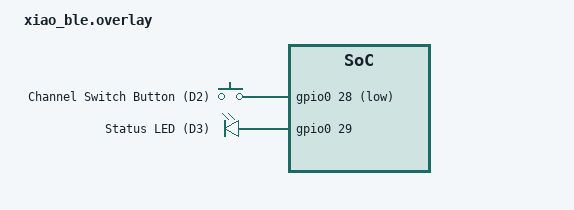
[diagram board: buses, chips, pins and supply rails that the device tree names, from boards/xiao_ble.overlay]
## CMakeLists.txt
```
cmake_minimum_required(VERSION 3.20.0)

find_package(Zephyr REQUIRED HINTS $ENV{ZEPHYR_BASE})
project(multichannel_ble_keyboard)

target_sources(app PRIVATE
    src/main.c
    src/hid_keyboard.c
)
```

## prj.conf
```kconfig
# ---------------------------------------------------------------------------
# Multi-Channel BLE Keyboard - prj.conf
# XIAO nRF52840 (Plus) + Zephyr
# ---------------------------------------------------------------------------

# --- GPIO (button + LED) ---
CONFIG_GPIO=y

# --- Bluetooth core ---
CONFIG_BT=y
CONFIG_BT_PERIPHERAL=y
CONFIG_BT_DEVICE_NAME="BTSwitchIRK"

# Allow multiple local identities = multiple "channels".
# Must be >= NUM_CHANNELS used in main.c (id 0 is the default identity).
CONFIG_BT_ID_MAX=4

# Only one *logical* BLE link at a time (one channel connected at once),
# but we allocate 2 connection object slots. Connectable advertising
# preallocates a connection object, and the object from the just-ended
# link may not be fully recycled yet at the moment we immediately start
# advertising again inside the disconnected() callback - see
# bt_conn_cb.recycled in Zephyr's docs. With only 1 slot this causes
# bt_le_adv_start() to intermittently fail with -ENOMEM right after a
# channel switch. 2 slots gives enough headroom.
CONFIG_BT_MAX_CONN=2

# Bond storage slots. Increase if you pair many different remote devices
# across all channels combined (each channel x each remote device = 1 bond).
CONFIG_BT_MAX_PAIRED=8

# --- Security / bonding ---
CONFIG_BT_SMP=y
CONFIG_BT_BONDABLE=y
# "Just Works" bonding, no passkey/display required. Change if you need
# MITM-protected pairing (then also register bt_conn_auth_cb callbacks).
CONFIG_BT_SMP_SC_PAIR_ONLY=n

# --- Persist bonds/keys across reboot ---
CONFIG_FLASH=y
CONFIG_FLASH_MAP=y
CONFIG_NVS=y
CONFIG_SETTINGS=y
CONFIG_BT_SETTINGS=y
CONFIG_REBOOT=y

# --- GATT ---
CONFIG_BT_GATT_DYNAMIC_DB=y

# --- Device Information Service (optional but recommended by most hosts) ---
CONFIG_BT_DIS=y
CONFIG_BT_DIS_PNP=y

# --- Battery Service (optional, remove if you don't report battery) ---
CONFIG_BT_BAS=y

# --- Logging ---
CONFIG_LOG=y
CONFIG_LOG_MODE_DEFERRED=y
CONFIG_PRINTK=y

# --- Stacks (BT + our callbacks can be stack-hungry, pad a bit) ---
CONFIG_MAIN_STACK_SIZE=4096
CONFIG_BT_HCI_TX_STACK_SIZE=2048
CONFIG_SYSTEM_WORKQUEUE_STACK_SIZE=2048
```

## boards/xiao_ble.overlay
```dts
/*
 * Devicetree overlay: channel-switch button + status LED.
 *
 * XIAO nRF52840 D-pin -> nRF52840 GPIO mapping used below:
 *   D2 -> P0.28  (channel switch button, pulled up, active low)
 *   D3 -> P0.29  (status LED, active high)
 *
 * If your board revision / wiring differs, just change the pin numbers.
 * Some newer Zephyr board files expose an "xiao_d" gpio nexus so you can
 * write `<&xiao_d 2 ...>` instead of `<&gpio0 28 ...>` - either form is
 * fine, use whichever your Zephyr version supports.
 */

/ {
	buttons {
		compatible = "gpio-keys";
		channel_button: channel_button {
			gpios = <&gpio0 28 (GPIO_PULL_UP | GPIO_ACTIVE_LOW)>;
			label = "Channel Switch Button (D2)";
		};
	};

	leds {
		compatible = "gpio-leds";
		status_led: status_led {
			gpios = <&gpio0 29 GPIO_ACTIVE_HIGH>;
			label = "Status LED (D3)";
		};
	};

	aliases {
		sw0 = &channel_button;
		led0 = &status_led;
	};
};
```

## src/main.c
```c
/*
 * Multi-Channel BLE Keyboard - XIAO nRF52840 (Plus) + Zephyr
 *
 * Each "channel" is backed by its own Bluetooth local identity (bt_id).
 * Because bonding/key storage in Zephyr's host stack is partitioned per
 * local identity, the SAME remote device (same IRK) can be paired to
 * MULTIPLE channels at once with no key-database collision -- each
 * channel keeps its own independent bond record for that phone.
 *
 * Button (default D2): press to advance to the next channel.
 *   - If currently connected, we disconnect first, then start
 *     advertising the next channel's identity once the disconnect
 *     callback confirms the link is actually closed.
 *   - If not connected, we switch immediately.
 *
 * LED (default D3): on solid while connected, off while advertising.
 */

#include <zephyr/kernel.h>
#include <zephyr/device.h>
#include <zephyr/devicetree.h>
#include <zephyr/drivers/gpio.h>
#include <zephyr/bluetooth/bluetooth.h>
#include <zephyr/bluetooth/conn.h>
#include <zephyr/bluetooth/hci.h>
#include <zephyr/bluetooth/gap.h>
#include <zephyr/bluetooth/uuid.h>
#include <zephyr/bluetooth/gatt.h>
#include <zephyr/settings/settings.h>
#include <zephyr/storage/flash_map.h>
#include <zephyr/sys/reboot.h>
#include <zephyr/logging/log.h>
#include <string.h>

#include "hid_keyboard.h"

LOG_MODULE_REGISTER(main, LOG_LEVEL_INF);

#define NUM_CHANNELS 3
#define DEBOUNCE_MS  40
#define FACTORY_RESET_HOLD_MS 3000

static const char * const channel_names[NUM_CHANNELS] = {
	"BTSwitchIRK_1",
	"BTSwitchIRK_2",
	"BTSwitchIRK_3",
};

static uint8_t channel_ids[NUM_CHANNELS];
static int active_channel;
static int pending_channel;
static bool switch_requested;
static struct bt_conn *current_conn;

/* ---------------- GPIO ---------------- */

static const struct gpio_dt_spec button = GPIO_DT_SPEC_GET(DT_ALIAS(sw0), gpios);
static const struct gpio_dt_spec led    = GPIO_DT_SPEC_GET(DT_ALIAS(led0), gpios);
static struct gpio_callback button_cb_data;
static struct k_work_delayable debounce_work;
static struct k_work_delayable adv_retry_work;
static int adv_retry_channel;

/* ---------------- Advertising data ---------------- */

static uint8_t adv_name_buf[32];

static struct bt_data ad[] = {
	BT_DATA_BYTES(BT_DATA_FLAGS, (BT_LE_AD_GENERAL | BT_LE_AD_NO_BREDR)),
	BT_DATA_BYTES(BT_DATA_GAP_APPEARANCE, 0xC1, 0x03), /* 0x03C1 = HID Keyboard */
	BT_DATA(BT_DATA_NAME_COMPLETE, adv_name_buf, 0),
};

static const struct bt_data sd[] = {
	BT_DATA_BYTES(BT_DATA_UUID16_ALL, 0x12, 0x18), /* 0x1812 = HID Service */
};

/* ---------------- Helpers ---------------- */

static void set_led(bool on)
{
	gpio_pin_set_dt(&led, on ? 1 : 0);
}

static void start_advertising(int idx)
{
	size_t name_len = strlen(channel_names[idx]);

	memcpy(adv_name_buf, channel_names[idx], name_len);
	ad[2].data_len = name_len;

	struct bt_le_adv_param adv_param = {
		.id = channel_ids[idx],
		.options = BT_LE_ADV_OPT_CONN,
		.interval_min = BT_GAP_ADV_FAST_INT_MIN_2,
		.interval_max = BT_GAP_ADV_FAST_INT_MAX_2,
	};

	int err = bt_le_adv_start(&adv_param, ad, ARRAY_SIZE(ad), sd, ARRAY_SIZE(sd));

	if (err == -ENOMEM) {
		/* The connection object from the previous link may not be
		 * fully recycled yet (see bt_conn_cb.recycled). Retry
		 * shortly instead of giving up on this channel.
		 */
		LOG_WRN("No free connection object yet for channel %d, retrying...", idx + 1);
		adv_retry_channel = idx;
		k_work_reschedule(&adv_retry_work, K_MSEC(50));
		return;
	}

	if (err) {
		LOG_ERR("Advertising failed to start for channel %d (err %d)", idx + 1, err);
		return;
	}

	set_led(false);
	printk("\n=================================\n");
	printk("正在廣播頻道 %d (%s)...\n", idx + 1, channel_names[idx]);
	printk("=================================\n");
}

static void do_channel_switch(void)
{
	active_channel = pending_channel;
	start_advertising(active_channel);
}

static void adv_retry_handler(struct k_work *work)
{
	start_advertising(adv_retry_channel);
}

/* ---------------- BLE connection callbacks ---------------- */

static void connected(struct bt_conn *conn, uint8_t err)
{
	if (err) {
		LOG_ERR("Connection failed (err %u)", err);
		return;
	}

	current_conn = bt_conn_ref(conn);
	set_led(true);
	printk("裝置已連線 (頻道 %d)\n", active_channel + 1);
}

static void disconnected(struct bt_conn *conn, uint8_t reason)
{
	printk("裝置已斷線 (原因: %u)\n", reason);

	if (current_conn) {
		bt_conn_unref(current_conn);
		current_conn = NULL;
	}

	hid_keyboard_notify_disconnected();
	set_led(false);

	if (switch_requested) {
		switch_requested = false;
		do_channel_switch();
	} else {
		/* Stay on the same channel so the bonded device can
		 * reconnect on its own.
		 */
		start_advertising(active_channel);
	}
}

BT_CONN_CB_DEFINE(conn_callbacks) = {
	.connected = connected,
	.disconnected = disconnected,
};

/* ---------------- Button handling ---------------- */

static void request_channel_switch(void)
{
	pending_channel = (active_channel + 1) % NUM_CHANNELS;
	switch_requested = true;

	printk("\n=================================\n");
	printk("按鈕已觸發，切換頻道中...\n");
	printk("=================================\n");

	bt_le_adv_stop();

	if (current_conn) {
		/* do_channel_switch() runs from disconnected() once the
		 * link is actually torn down - don't race it here.
		 */
		bt_conn_disconnect(current_conn, BT_HCI_ERR_REMOTE_USER_TERM_CONN);
	} else {
		switch_requested = false;
		do_channel_switch();
	}
}

static void debounce_handler(struct k_work *work)
{
	if (gpio_pin_get_dt(&button)) {
		request_channel_switch();
	}
}

static void button_pressed(const struct device *dev, struct gpio_callback *cb, uint32_t pins)
{
	k_work_reschedule(&debounce_work, K_MSEC(DEBOUNCE_MS));
}

static int setup_gpio(void)
{
	int err;

	if (!gpio_is_ready_dt(&button) || !gpio_is_ready_dt(&led)) {
		LOG_ERR("GPIO device not ready");
		return -ENODEV;
	}

	err = gpio_pin_configure_dt(&button, GPIO_INPUT);
	if (err) {
		return err;
	}

	err = gpio_pin_configure_dt(&led, GPIO_OUTPUT_INACTIVE);
	if (err) {
		return err;
	}

	err = gpio_pin_interrupt_configure_dt(&button, GPIO_INT_EDGE_TO_ACTIVE);
	if (err) {
		return err;
	}

	gpio_init_callback(&button_cb_data, button_pressed, BIT(button.pin));
	gpio_add_callback(button.port, &button_cb_data);

	k_work_init_delayable(&debounce_work, debounce_handler);
	k_work_init_delayable(&adv_retry_work, adv_retry_handler);

	return 0;
}

/* ---------------- Identity setup ---------------- */

static void setup_identities(void)
{
	channel_ids[0] = BT_ID_DEFAULT;

	for (int i = 1; i < NUM_CHANNELS; i++) {
		int id = bt_id_create(NULL, NULL);

		if (id < 0) {
			LOG_ERR("bt_id_create failed for channel %d (err %d)", i + 1, id);
			channel_ids[i] = BT_ID_DEFAULT;
		} else {
			channel_ids[i] = (uint8_t)id;
		}
	}
}

/* ---------------- Factory reset (no SWD/nrfjprog needed) ----------------
 *
 * Since flashing via UF2 drag-and-drop only overwrites the application
 * region and never touches the dedicated storage/NVS partition, stale
 * bonding data can survive across reflashes and cause settings_load()
 * failures. This lets you wipe just that partition from within the
 * firmware itself: hold the channel button while powering on / resetting
 * the board (double-tap reset into UF2 mode still works exactly the same
 * as before; this check only runs during normal firmware boot).
 */
static void check_factory_reset(void)
{
	if (!gpio_pin_get_dt(&button)) {
		return; /* button not held at boot, nothing to do */
	}

	printk("偵測到開機時按住按鈕，請繼續按住 %d 秒以清除所有配對資料...\n",
	       FACTORY_RESET_HOLD_MS / 1000);

	int64_t start = k_uptime_get();

	while (gpio_pin_get_dt(&button)) {
		if (k_uptime_get() - start >= FACTORY_RESET_HOLD_MS) {
			break;
		}
		k_msleep(50);
	}

	if (k_uptime_get() - start < FACTORY_RESET_HOLD_MS) {
		printk("按住時間不足，取消清除，正常開機。\n");
		return;
	}

	printk("清除中，請勿斷電...\n");

	const struct flash_area *fa;
	int rc = flash_area_open(FIXED_PARTITION_ID(storage_partition), &fa);

	if (rc) {
		LOG_ERR("flash_area_open failed (%d)", rc);
		return;
	}

	rc = flash_area_erase(fa, 0, fa->fa_size);
	flash_area_close(fa);

	if (rc) {
		LOG_ERR("flash_area_erase failed (%d)", rc);
		return;
	}

	printk("記憶已清除！3 秒後自動重新開機，請放開按鈕...\n");
	k_msleep(3000);
	sys_reboot(SYS_REBOOT_COLD);
	/* unreachable */
}

/* ---------------- Main ---------------- */

int main(void)
{
	int err;

	printk("*** Multi-Channel BLE Keyboard ***\n");

	err = setup_gpio();
	if (err) {
		LOG_ERR("GPIO setup failed (%d)", err);
	}

	err = bt_enable(NULL);
	if (err) {
		LOG_ERR("bt_enable failed (%d)", err);
		return 0;
	}

	check_factory_reset();

	if (IS_ENABLED(CONFIG_SETTINGS)) {
		settings_load();
	}

	setup_identities();
	hid_keyboard_init();

	start_advertising(active_channel);

	return 0;
}
```

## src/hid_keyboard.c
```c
/*
 * Minimal HID-over-GATT (HOGP) keyboard service.
 *
 * Vanilla Zephyr does not ship a ready-made "bt_hids" library (that only
 * exists in Nordic's nRF Connect SDK). This file implements the small
 * subset of the HID service needed for a standard boot-protocol keyboard:
 *   - HID Information
 *   - Report Map (the HID report descriptor)
 *   - Input Report (notify) + CCC + Report Reference descriptor
 *   - Output Report (write) + Report Reference descriptor  (LED state)
 *   - HID Control Point (write)
 */

#include <zephyr/kernel.h>
#include <zephyr/bluetooth/bluetooth.h>
#include <zephyr/bluetooth/conn.h>
#include <zephyr/bluetooth/gatt.h>
#include <zephyr/bluetooth/uuid.h>
#include <string.h>
#include <errno.h>

#include "hid_keyboard.h"

enum {
	HIDS_INPUT   = 0x01,
	HIDS_OUTPUT  = 0x02,
	HIDS_FEATURE = 0x03,
};

enum {
	HIDS_NORMALLY_CONNECTABLE = BIT(1),
};

struct hids_info {
	uint16_t version;
	uint8_t  country_code;
	uint8_t  flags;
} __packed;

struct hids_report_ref {
	uint8_t id;
	uint8_t type;
} __packed;

/* Standard USB HID boot-keyboard report descriptor:
 * 1 modifier byte + 1 reserved byte + 6 keycode bytes = 8-byte report.
 */
static const uint8_t hid_report_map_data[] = {
	0x05, 0x01, /* Usage Page (Generic Desktop) */
	0x09, 0x06, /* Usage (Keyboard) */
	0xA1, 0x01, /* Collection (Application) */
	0x85, 0x01, /*   Report Id (1) */
	0x05, 0x07, /*   Usage Page (Key Codes) */
	0x19, 0xE0, /*   Usage Minimum (224) */
	0x29, 0xE7, /*   Usage Maximum (231) */
	0x15, 0x00, /*   Logical Minimum (0) */
	0x25, 0x01, /*   Logical Maximum (1) */
	0x75, 0x01, /*   Report Size (1) */
	0x95, 0x08, /*   Report Count (8) */
	0x81, 0x02, /*   Input (Data, Variable, Absolute) - modifier byte */
	0x95, 0x01, /*   Report Count (1) */
	0x75, 0x08, /*   Report Size (8) */
	0x81, 0x01, /*   Input (Constant) - reserved byte */
	0x95, 0x05, /*   Report Count (5) */
	0x75, 0x01, /*   Report Size (1) */
	0x05, 0x08, /*   Usage Page (LEDs) */
	0x19, 0x01, /*   Usage Minimum (1) */
	0x29, 0x05, /*   Usage Maximum (5) */
	0x91, 0x02, /*   Output (Data, Variable, Absolute) - LED report */
	0x95, 0x01, /*   Report Count (1) */
	0x75, 0x03, /*   Report Size (3) */
	0x91, 0x01, /*   Output (Constant) - LED report padding */
	0x95, 0x06, /*   Report Count (6) */
	0x75, 0x08, /*   Report Size (8) */
	0x15, 0x00, /*   Logical Minimum (0) */
	0x25, 0x65, /*   Logical Maximum (101) */
	0x05, 0x07, /*   Usage Page (Key Codes) */
	0x19, 0x00, /*   Usage Minimum (0) */
	0x29, 0x65, /*   Usage Maximum (101) */
	0x81, 0x00, /*   Input (Data, Array) - up to 6 simultaneous keys */
	0xC0        /* End Collection */
};

static const struct hids_info info = {
	.version = 0x0000,
	.country_code = 0x00,
	.flags = HIDS_NORMALLY_CONNECTABLE,
};

static const struct hids_report_ref input_report_ref  = { .id = 0x01, .type = HIDS_INPUT };
static const struct hids_report_ref output_report_ref = { .id = 0x01, .type = HIDS_OUTPUT };

static uint8_t input_report[8];
static uint8_t output_report_value[1];
static uint8_t ctrl_point_value;
static bool notifications_enabled;

/* --- GATT read/write callbacks --- */

static ssize_t read_info(struct bt_conn *conn, const struct bt_gatt_attr *attr,
			  void *buf, uint16_t len, uint16_t offset)
{
	return bt_gatt_attr_read(conn, attr, buf, len, offset, &info, sizeof(info));
}

static ssize_t read_report_map(struct bt_conn *conn, const struct bt_gatt_attr *attr,
				void *buf, uint16_t len, uint16_t offset)
{
	return bt_gatt_attr_read(conn, attr, buf, len, offset,
				  hid_report_map_data, sizeof(hid_report_map_data));
}

static ssize_t read_input_report(struct bt_conn *conn, const struct bt_gatt_attr *attr,
				  void *buf, uint16_t len, uint16_t offset)
{
	return bt_gatt_attr_read(conn, attr, buf, len, offset,
				  input_report, sizeof(input_report));
}

static ssize_t read_report_ref(struct bt_conn *conn, const struct bt_gatt_attr *attr,
				void *buf, uint16_t len, uint16_t offset)
{
	const struct hids_report_ref *ref = attr->user_data;

	return bt_gatt_attr_read(conn, attr, buf, len, offset, ref, sizeof(*ref));
}

static void input_ccc_changed(const struct bt_gatt_attr *attr, uint16_t value)
{
	notifications_enabled = (value == BT_GATT_CCC_NOTIFY);
}

static ssize_t write_output_report(struct bt_conn *conn, const struct bt_gatt_attr *attr,
				    const void *buf, uint16_t len, uint16_t offset, uint8_t flags)
{
	uint8_t *value = attr->user_data;

	if (offset + len > sizeof(output_report_value)) {
		return BT_GATT_ERR(BT_ATT_ERR_INVALID_OFFSET);
	}

	memcpy(value + offset, buf, len);
	/* value[0] bit0 = Num Lock, bit1 = Caps Lock, bit2 = Scroll Lock, etc. */
	return len;
}

static ssize_t write_ctrl_point(struct bt_conn *conn, const struct bt_gatt_attr *attr,
				 const void *buf, uint16_t len, uint16_t offset, uint8_t flags)
{
	uint8_t *value = attr->user_data;

	if (offset + len > sizeof(ctrl_point_value)) {
		return BT_GATT_ERR(BT_ATT_ERR_INVALID_OFFSET);
	}

	memcpy(value + offset, buf, len);
	return len;
}

/*
 * Service layout (attribute indices, for reference - see hid_keyboard_send_report):
 *  0  Primary Service
 *  1  Characteristic Decl - HID Information
 *  2  Value               - HID Information
 *  3  Characteristic Decl - Report Map
 *  4  Value               - Report Map
 *  5  Characteristic Decl - Report (Input)
 *  6  Value               - Input Report   <-- notify target
 *  7  CCC
 *  8  Descriptor           - Report Reference (Input)
 *  9  Characteristic Decl - Report (Output)
 * 10  Value               - Output Report
 * 11  Descriptor           - Report Reference (Output)
 * 12  Characteristic Decl - HID Control Point
 * 13  Value               - HID Control Point
 */
BT_GATT_SERVICE_DEFINE(hids_svc,
	BT_GATT_PRIMARY_SERVICE(BT_UUID_HIDS),

	BT_GATT_CHARACTERISTIC(BT_UUID_HIDS_INFO, BT_GATT_CHRC_READ,
				BT_GATT_PERM_READ, read_info, NULL, NULL),

	BT_GATT_CHARACTERISTIC(BT_UUID_HIDS_REPORT_MAP, BT_GATT_CHRC_READ,
				BT_GATT_PERM_READ, read_report_map, NULL, NULL),

	BT_GATT_CHARACTERISTIC(BT_UUID_HIDS_REPORT,
				BT_GATT_CHRC_READ | BT_GATT_CHRC_NOTIFY,
				BT_GATT_PERM_READ, read_input_report, NULL, NULL),
	BT_GATT_CCC(input_ccc_changed, BT_GATT_PERM_READ | BT_GATT_PERM_WRITE),
	BT_GATT_DESCRIPTOR(BT_UUID_HIDS_REPORT_REF, BT_GATT_PERM_READ,
			   read_report_ref, NULL, (void *)&input_report_ref),

	BT_GATT_CHARACTERISTIC(BT_UUID_HIDS_REPORT,
				BT_GATT_CHRC_WRITE | BT_GATT_CHRC_WRITE_WITHOUT_RESP,
				BT_GATT_PERM_WRITE, NULL, write_output_report,
				output_report_value),
	BT_GATT_DESCRIPTOR(BT_UUID_HIDS_REPORT_REF, BT_GATT_PERM_READ,
			   read_report_ref, NULL, (void *)&output_report_ref),

	BT_GATT_CHARACTERISTIC(BT_UUID_HIDS_CTRL_POINT,
				BT_GATT_CHRC_WRITE_WITHOUT_RESP,
				BT_GATT_PERM_WRITE, NULL, write_ctrl_point,
				&ctrl_point_value),
);

#define INPUT_REPORT_VALUE_ATTR (&hids_svc.attrs[6])

void hid_keyboard_init(void)
{
	memset(input_report, 0, sizeof(input_report));
	notifications_enabled = false;
}

void hid_keyboard_notify_disconnected(void)
{
	notifications_enabled = false;
}

int hid_keyboard_send_report(struct bt_conn *conn, uint8_t modifier,
			      const uint8_t keycodes[6])
{
	if (!conn || !notifications_enabled) {
		return -ENOTCONN;
	}

	input_report[0] = modifier;
	input_report[1] = 0x00; /* reserved */
	memcpy(&input_report[2], keycodes, 6);

	return bt_gatt_notify(conn, INPUT_REPORT_VALUE_ATTR, input_report, sizeof(input_report));
}

int hid_keyboard_send_key(struct bt_conn *conn, uint8_t modifier, uint8_t keycode)
{
	uint8_t keys_down[6] = { keycode, 0, 0, 0, 0, 0 };
	uint8_t keys_up[6]   = { 0 };
	int err;

	err = hid_keyboard_send_report(conn, modifier, keys_down);
	if (err) {
		return err;
	}

	k_sleep(K_MSEC(10));

	return hid_keyboard_send_report(conn, 0, keys_up);
}
```

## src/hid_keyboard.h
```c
#ifndef HID_KEYBOARD_H_
#define HID_KEYBOARD_H_

#include <zephyr/bluetooth/conn.h>
#include <stdint.h>

/* Call once at boot, after bt_enable(). Currently just resets internal state,
 * but kept as a hook so you can extend it later (e.g. load a saved LED
 * output state).
 */
void hid_keyboard_init(void);

/* Call from your BT disconnected callback so the service stops trying to
 * notify a report on a link that no longer exists.
 */
void hid_keyboard_notify_disconnected(void);

/* Send one 8-byte HID boot-keyboard report:
 *   modifier : bitfield, bit0=LCtrl bit1=LShift bit2=LAlt bit3=LGUI
 *              bit4=RCtrl bit5=RShift bit6=RAlt bit7=RGUI
 *   keycodes : up to 6 simultaneous USB HID keycodes (0 = no key)
 *
 * Returns 0 on success, -ENOTCONN if not connected / notifications not
 * enabled (host hasn't written CCC yet), or a negative bt_gatt_notify() error.
 */
int hid_keyboard_send_report(struct bt_conn *conn, uint8_t modifier,
			      const uint8_t keycodes[6]);

/* Convenience: send a single keycode, then immediately send an all-zero
 * "key released" report. Useful for a simple button-triggers-one-keystroke
 * setup.
 */
int hid_keyboard_send_key(struct bt_conn *conn, uint8_t modifier, uint8_t keycode);

#endif /* HID_KEYBOARD_H_ */
```
